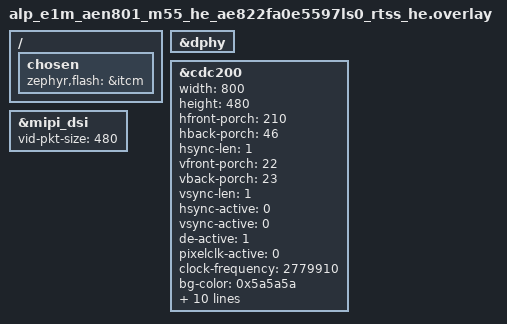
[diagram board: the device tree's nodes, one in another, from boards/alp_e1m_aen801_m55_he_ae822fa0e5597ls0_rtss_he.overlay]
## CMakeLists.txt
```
# SPDX-License-Identifier: Apache-2.0
#
# aen-dsi-regcheck -- scopeless on-silicon staging check of the Alif C2-MIPI-DSI
# DISPLAY chain (cdc200 "tes,cdc-2.1" -> mipi_dsi "snps,designware-dsi" -> the
# shared D-PHY "snps,designware-dphy") on the E1M-AEN801 (Ensemble E8, M55-HE),
# via the bench RAM-run + RAM-console flow.  The CSI/RX twin of this app is
# aen-camera-firstlight.
#
# Plain prj.conf app (no alp_project.py board.yaml emit).  This is a BIND check:
# it instantiates nothing new -- the dphy already has an in-tree driver (its TX
# role is dphy_dw_master_setup); cdc200/mipi_dsi class drivers are intentionally
# not enabled here, so they bind at DT level only.  Use aen-dsi-display for the
# live display-driver path.  The cdc200 + mipi_dsi nodes are supplied by the
# board overlay.  See src/main.c.

cmake_minimum_required(VERSION 3.20)

find_package(Zephyr REQUIRED HINTS $ENV{ZEPHYR_BASE})
project(aen_dsi_regcheck LANGUAGES C)

target_sources(app PRIVATE src/main.c)
```

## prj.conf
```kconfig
# SPDX-License-Identifier: Apache-2.0
#
# Bench config for the E1M-AEN801 (M55-HE).  Console is the E1M edge UART0.

# Tier-2 driver Kconfigs (incl. CONFIG_MIPI_DPHY_DW) are gated under ALP_SDK.
CONFIG_ALP_SDK=y

# The shared DesignWare MIPI D-PHY (the one display-chain node that already has
# a real in-tree driver; its DSI-TX role is dphy_dw_master_setup()).  Enabled by
# the overlay; its driver Kconfig is default y under DT_HAS_*_ENABLED.
CONFIG_MIPI_DPHY=y

# No display/mipi_dsi-class driver is enabled here: this app remains a BIND
# check.  Use aen-dsi-display for the live cdc200 + DesignWare DSI driver path
# and pixels-on-glass bench proof.

# Console: Alp UART console -- E1M edge UART0 (Alif UART5, P3_4/P3_5, 115200
# 8N1, NS16550), the E1M-AEN801 carrier console. The board _defconfig already
# selects it; we set it explicitly here so the example is self-describing.
CONFIG_SERIAL=y
CONFIG_CONSOLE=y
CONFIG_UART_CONSOLE=y
CONFIG_UART_INTERRUPT_DRIVEN=y
# Serial-less bench? Comment the four lines above and uncomment these to read
# 'ram_console_buf' over SWD instead:
# CONFIG_RAM_CONSOLE=y
# CONFIG_RAM_CONSOLE_BUFFER_SIZE=2048
# CONFIG_UART_CONSOLE=n
CONFIG_PRINTK=y

# Keep the image small + deterministic for a RAM-run.
CONFIG_LOG=n
```

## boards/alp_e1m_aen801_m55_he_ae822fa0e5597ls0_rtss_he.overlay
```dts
/*
 * Copyright (c) 2026 Alp Lab AB
 * SPDX-License-Identifier: Apache-2.0
 *
 * aen-dsi-regcheck overlay for the E1M-AEN801 (Ensemble E8, M55-HE) RAM-run.
 *
 * Stages the C2-MIPI-DSI DISPLAY chain so every node BINDS on silicon:
 *   - cdc200   (tes,cdc-2.1            @ 0x49031000) -- the DPI/RGB pixel pump
 *   - mipi_dsi (snps,designware-dsi    @ 0x49032000) -- the MIPI-DSI host (TX)
 *   - dphy     (snps,designware-dphy   @ 0x49033000) -- the shared D-PHY (TX role)
 *
 * All three nodes, with their SoC facts (reg, IRQs, clocks, the cdc-if /
 * phy-if wiring), are defined disabled in zephyr/dts/alif/
 * ensemble_e8_peripherals.dtsi; this overlay only turns them on.  An okay
 * cdc200 needs a panel's width/height/timings (the binding requires them), so
 * it gets placeholder values here -- this bind-only app does not enable the
 * live display-class drivers.  Use aen-dsi-display (the
 * e1m_evk_rk055hdmipi4ma0 shield) for the panel + driver path.
 *
 * SCOPE: this proves the chain BINDS (DT_HAS_*_ENABLED + phandle wiring).  It
 * deliberately omits panel children and reset/backlight GPIOs; live output is
 * covered by the separate aen-dsi-display bench app.
 */

/*
 * RAM-run: retarget ROM to ITCM (path-reference form &itcm; the phandle-array
 * form makes FLASH_SIZE=0 and overflows the link).
 */
/ {
	chosen {
		zephyr,flash = &itcm;
		/delete-property/ zephyr,code-partition;
	};
};

&dphy {
	status = "okay";
};

&cdc200 {
	/* Placeholder timing for bind-only validation. */
	width = <800>;
	height = <480>;
	hfront-porch = <210>;
	hback-porch = <46>;
	hsync-len = <1>;
	vfront-porch = <22>;
	vback-porch = <23>;
	vsync-len = <1>;
	hsync-active = <0>;
	vsync-active = <0>;
	de-active = <1>;
	pixelclk-active = <0>;
	clock-frequency = <2779910>;
	bg-color = <0x5a5a5a>;

	enable-l1 = <1>;
	pixel-fmt-l1 = "rgb-565";
	def-back-color-l1 = <0x00ff00>;
	win-x0-l1 = <0>;
	win-y0-l1 = <0>;
	win-x1-l1 = <800>;
	win-y1-l1 = <480>;
	blend-factor1-l1 = <4>;
	blend-factor2-l1 = <5>;
	const-alpha-l1 = <0xff>;

	status = "okay";
};

/* No panel child here; aen-dsi-display carries the live panel path. */
&mipi_dsi {
	vid-pkt-size = <480>;
	status = "okay";
};
```

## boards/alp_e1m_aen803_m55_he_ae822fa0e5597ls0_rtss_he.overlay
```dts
/*
 * Copyright (c) 2026 Alp Lab AB
 * SPDX-License-Identifier: Apache-2.0
 *
 * aen-dsi-regcheck overlay for the E1M-AEN803 (Ensemble E8, M55-HE) RAM-run.
 *
 * Stages the C2-MIPI-DSI DISPLAY chain so every node BINDS on silicon:
 *   - cdc200   (tes,cdc-2.1            @ 0x49031000) -- the DPI/RGB pixel pump
 *   - mipi_dsi (snps,designware-dsi    @ 0x49032000) -- the MIPI-DSI host (TX)
 *   - dphy     (snps,designware-dphy   @ 0x49033000) -- the shared D-PHY (TX role)
 *
 * All three nodes, with their SoC facts (reg, IRQs, clocks, the cdc-if /
 * phy-if wiring), are defined disabled in zephyr/dts/alif/
 * ensemble_e8_peripherals.dtsi; this overlay only turns them on.  An okay
 * cdc200 needs a panel's width/height/timings (the binding requires them), so
 * it gets placeholder values here -- this bind-only app does not enable the
 * live display-class drivers.  Use aen-dsi-display (the
 * e1m_evk_rk055hdmipi4ma0 shield) for the panel + driver path.
 *
 * SCOPE: this proves the chain BINDS (DT_HAS_*_ENABLED + phandle wiring).  It
 * deliberately omits panel children and reset/backlight GPIOs; live output is
 * covered by the separate aen-dsi-display bench app.
 */

/*
 * RAM-run: retarget ROM to ITCM (path-reference form &itcm; the phandle-array
 * form makes FLASH_SIZE=0 and overflows the link).
 */
/ {
	chosen {
		zephyr,flash = &itcm;
		/delete-property/ zephyr,code-partition;
	};
};

&dphy {
	status = "okay";
};

&cdc200 {
	/* Placeholder timing for bind-only validation. */
	width = <800>;
	height = <480>;
	hfront-porch = <210>;
	hback-porch = <46>;
	hsync-len = <1>;
	vfront-porch = <22>;
	vback-porch = <23>;
	vsync-len = <1>;
	hsync-active = <0>;
	vsync-active = <0>;
	de-active = <1>;
	pixelclk-active = <0>;
	clock-frequency = <2779910>;
	bg-color = <0x5a5a5a>;

	enable-l1 = <1>;
	pixel-fmt-l1 = "rgb-565";
	def-back-color-l1 = <0x00ff00>;
	win-x0-l1 = <0>;
	win-y0-l1 = <0>;
	win-x1-l1 = <800>;
	win-y1-l1 = <480>;
	blend-factor1-l1 = <4>;
	blend-factor2-l1 = <5>;
	const-alpha-l1 = <0xff>;

	status = "okay";
};

/* No panel child here; aen-dsi-display carries the live panel path. */
&mipi_dsi {
	vid-pkt-size = <480>;
	status = "okay";
};
```

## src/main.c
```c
/*
 * Copyright (c) 2026 Alp Lab AB
 * SPDX-License-Identifier: Apache-2.0
 *
 * aen-dsi-regcheck -- scopeless on-silicon staging check of the Alif C2-MIPI-DSI
 * DISPLAY stack on the E1M-AEN801 (Ensemble E8, M55-HE), via the bench RAM-run +
 * RAM-console flow.  Mirrors aen-camera-firstlight (the CSI/RX twin of this path).
 *
 * THE DISPLAY CHAIN (C2-MIPI-DSI):
 *
 *   cdc200@49031000  (tes,cdc-2.1)          -- the DPI/RGB pixel pump (CDC200)
 *       |  DPI
 *   mipi_dsi@49032000 (snps,designware-dsi) -- the MIPI-DSI host (DSI-TX bridge)
 *       |  phy-if <&dphy 1>
 *   dphy@49033000    (snps,designware-dphy) -- the shared DesignWare MIPI D-PHY
 *
 * The shared D-PHY is the SAME block the camera path uses for CSI-2 RX; for the
 * display path it runs in the TX role.  That TX role is implemented in
 * zephyr/drivers/mipi_dphy/dphy_dw.c (dphy_dw_master_setup(), which programs the
 * PHY via the node's "dsi_reg" 0x49032000 view).
 *
 * WHAT THIS APP VALIDATES (and what it deliberately does NOT):
 *
 *   This is a BIND/instantiation check, not a pixels-on-glass check.  This app
 *   intentionally leaves the live cdc200 + mipi_dsi drivers off and proves the
 *   DT plumbing is still correct:
 *     1. the cdc200 + mipi_dsi + dphy nodes exist and BIND to their expected
 *        compatibles (tes,cdc-2.1 / snps,designware-dsi / snps,designware-dphy),
 *     2. the reg base each node carries matches the Alif CMSIS DFP / fork e1.dtsi
 *        addresses (CDC 0x49031000, DSI 0x49032000, D-PHY 0x49033000),
 *     3. the DSI host's cdc-if phandle resolves to the cdc200 node and its
 *        phy-if phandle resolves to the dphy node (the chain is wired),
 *     4. the dphy device (already a real in-tree driver) reports device_is_ready.
 *
 * LIVE DISPLAY OUTPUT: use aen-dsi-display.  This regcheck deliberately omits
 * panel child nodes and panel reset/backlight GPIOs so it remains a minimal
 * binding smoke test.
 *
 * The PASS gate is BIND-based: the cdc200 -> mipi_dsi -> dphy chain binds to its
 * expected compatibles at its expected reg bases, with the DSI host's cdc-if and
 * phy-if phandles resolving to the right nodes.  device_is_ready is reported for
 * the dphy; the cdc200/mipi_dsi "ready" state is not gated because this app does
 * not enable those drivers.
 */

#include <stdbool.h>
#include <stdint.h>

#include <zephyr/kernel.h>
#include <zephyr/device.h>
#include <zephyr/devicetree.h>
#include <zephyr/sys/printk.h>

/* The three display-chain nodes (enabled by the board overlay). */
#define CDC_NODE  DT_NODELABEL(cdc200)
#define DSI_NODE  DT_NODELABEL(mipi_dsi)
#define DPHY_NODE DT_NODELABEL(dphy)

/*
 * Expected reg bases, transcribed from the Alif CMSIS DFP SoC header
 * (Device/soc/AE822FA0E5597/include/rtss_he/soc.h: CDC_BASE 0x49031000,
 * DSI_BASE 0x49032000) and the fork e1.dtsi (d-phy@49033000).  We read the LIVE
 * value from devicetree and compare -- so a binding that resolved to the wrong
 * node is caught.
 */
#define CDC_BASE_EXPECTED  0x49031000U
#define DSI_BASE_EXPECTED  0x49032000U
#define DPHY_BASE_EXPECTED 0x49033000U /* dphy reg[0] "csi_reg" is the shared base */

/*
 * Compile-time staging facts -- each is 1 iff the node exists, is enabled, and
 * binds to its expected compatible.  Pure DT predicates, independent of
 * device_is_ready (no display driver instantiates cdc200/mipi_dsi yet).
 */
#define CDC_BOUND (DT_NODE_HAS_STATUS(CDC_NODE, okay) && DT_NODE_HAS_COMPAT(CDC_NODE, tes_cdc_2_1))
#define DSI_BOUND \
	(DT_NODE_HAS_STATUS(DSI_NODE, okay) && DT_NODE_HAS_COMPAT(DSI_NODE, snps_designware_dsi))
#define DPHY_BOUND \
	(DT_NODE_HAS_STATUS(DPHY_NODE, okay) && DT_NODE_HAS_COMPAT(DPHY_NODE, snps_designware_dphy))

/*
 * Chain-wiring facts: the DSI host's cdc-if phandle must resolve to the cdc200
 * node, and its phy-if phandle must resolve to the dphy node.  DT_SAME_NODE on
 * the resolved phandle is a build-time constant.
 */
#define DSI_CDC_IF_OK DT_SAME_NODE(DT_PHANDLE(DSI_NODE, cdc_if), CDC_NODE)
#define DSI_PHY_IF_OK DT_SAME_NODE(DT_PHANDLE_BY_IDX(DSI_NODE, phy_if, 0), DPHY_NODE)

static void report_ready(const char *name, const struct device *dev)
{
	if (dev == NULL) {
		printk("%-7s device : <none> (node disabled or no driver built)\n", name);
		return;
	}
	if (!device_is_ready(dev)) {
		printk("%-7s device : present but NOT ready\n", name);
		return;
	}
	printk("%-7s device : READY\n", name);
}

int main(void)
{
	printk("\n=== aen-dsi-regcheck ===\n");

	/*
	 * Step 1+2: report each node's binding + reg base.  DT_REG_ADDR is a
	 * build-time constant from the bound node; a mismatch vs the DFP/fork
	 * address means the binding resolved to the wrong node.
	 */
	uint32_t cdc_base  = (uint32_t)DT_REG_ADDR(CDC_NODE);
	uint32_t dsi_base  = (uint32_t)DT_REG_ADDR(DSI_NODE);
	uint32_t dphy_base = (uint32_t)DT_REG_ADDR(DPHY_NODE);

	printk("cdc200 : %s\n", DT_NODE_FULL_NAME(CDC_NODE));
	printk("         bound=%d compat=tes,cdc-2.1 base=0x%08x (exp 0x%08x)\n",
	       (int)CDC_BOUND,
	       cdc_base,
	       CDC_BASE_EXPECTED);
	printk("mipidsi: %s\n", DT_NODE_FULL_NAME(DSI_NODE));
	printk("         bound=%d compat=snps,designware-dsi base=0x%08x (exp 0x%08x)\n",
	       (int)DSI_BOUND,
	       dsi_base,
	       DSI_BASE_EXPECTED);
	printk("dphy   : %s\n", DT_NODE_FULL_NAME(DPHY_NODE));
	printk("         bound=%d compat=snps,designware-dphy base=0x%08x (exp 0x%08x)\n",
	       (int)DPHY_BOUND,
	       dphy_base,
	       DPHY_BASE_EXPECTED);

	/* Step 3: the chain is wired (DSI -> CDC source, DSI -> D-PHY TX). */
	printk("chain  : dsi.cdc-if->cdc200=%d  dsi.phy-if->dphy=%d\n",
	       (int)DSI_CDC_IF_OK,
	       (int)DSI_PHY_IF_OK);

	/*
	 * Step 4: dphy is enabled in this bind-only app, so it has a real device and
	 * can report device_is_ready.  cdc200/mipi_dsi are intentionally not enabled
	 * here; their bind is a pure DT fact above.
	 */
	printk("cdc200  device : <driver not enabled in this app -- DT-bind only>\n");
	printk("mipidsi device : <driver not enabled in this app -- DT-bind only>\n");
	report_ready("dphy", DEVICE_DT_GET_OR_NULL(DPHY_NODE));

	bool nodes_ok = CDC_BOUND && (cdc_base == CDC_BASE_EXPECTED) && DSI_BOUND &&
	                (dsi_base == DSI_BASE_EXPECTED) && DPHY_BOUND &&
	                (dphy_base == DPHY_BASE_EXPECTED) && DSI_CDC_IF_OK && DSI_PHY_IF_OK;

	if (nodes_ok) {
		printk("RESULT PASS: C2-MIPI-DSI display chain BINDS -- cdc200/mipi_dsi/dphy bind to "
		       "tes,cdc-2.1/snps,designware-dsi/snps,designware-dphy at the DFP reg bases "
		       "(CDC 0x49031000, DSI 0x49032000, D-PHY 0x49033000) with the dsi->cdc-if and "
		       "dsi->phy-if phandles wired; live display output is covered by aen-dsi-display\n");
	} else {
		printk("RESULT FAIL: C2-MIPI-DSI display chain NOT fully staged "
		       "(cdc=%d dsi=%d dphy=%d cdc-if=%d phy-if=%d -- a node is missing, disabled, "
		       "bound to the wrong compatible/reg base, or the chain phandles are unwired)\n",
		       (int)(CDC_BOUND && cdc_base == CDC_BASE_EXPECTED),
		       (int)(DSI_BOUND && dsi_base == DSI_BASE_EXPECTED),
		       (int)(DPHY_BOUND && dphy_base == DPHY_BASE_EXPECTED),
		       (int)DSI_CDC_IF_OK,
		       (int)DSI_PHY_IF_OK);
	}

	return 0;
}
```
